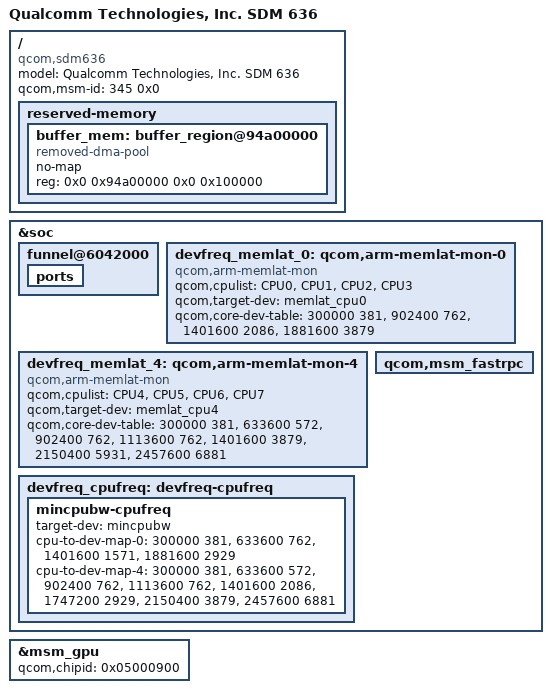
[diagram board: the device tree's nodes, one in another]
/* Copyright (c) 2017-2018, The Linux Foundation. All rights reserved.
 *
 * This program is free software; you can redistribute it and/or modify
 * it under the terms of the GNU General Public License version 2 and
 * only version 2 as published by the Free Software Foundation.
 *
 * This program is distributed in the hope that it will be useful,
 * but WITHOUT ANY WARRANTY; without even the implied warranty of
 * MERCHANTABILITY or FITNESS FOR A PARTICULAR PURPOSE.  See the
 * GNU General Public License for more details.
 */

#include "sdm660.dtsi"

/ {
	model = "Qualcomm Technologies, Inc. SDM 636";
	compatible = "qcom,sdm636";
	qcom,msm-id = <345 0x0>;

	reserved-memory {
		/delete-node/ cdsp_fw_region@94a00000;

		buffer_mem: buffer_region@94a00000 {
			compatible = "removed-dma-pool";
			no-map;
			reg = <0x0 0x94a00000 0x0 0x100000>;
		};
	};
};

&soc {
	/delete-node/ qcom,turing@1a300000;

	/delete-node/ qcom,msm-cdsp-loader;
	/delete-node/ cti@7068000;
	/delete-node/ turing_etm0;
	funnel@6042000 {
		ports {
			/delete-node/ port@4;
		};
	};

	devfreq_memlat_0: qcom,arm-memlat-mon-0 {
		compatible = "qcom,arm-memlat-mon";
		qcom,cpulist = <&CPU0 &CPU1 &CPU2 &CPU3>;
		qcom,target-dev = <&memlat_cpu0>;
		qcom,core-dev-table =
			< 300000 381 >,
			< 902400 762 >,
			< 1401600 2086 >,
			< 1881600 3879 >;
	};

	devfreq_memlat_4: qcom,arm-memlat-mon-4 {
		compatible = "qcom,arm-memlat-mon";
		qcom,cpulist = <&CPU4 &CPU5 &CPU6 &CPU7>;
		qcom,target-dev = <&memlat_cpu4>;
		qcom,core-dev-table =
			< 300000 381 >,
			< 633600 572 >,
			< 902400 762 >,
			< 1113600 762 >,
			< 1401600 3879 >,
			< 2150400 5931 >,
			< 2457600 6881 >;
	};

	devfreq_cpufreq: devfreq-cpufreq {
		mincpubw-cpufreq {
			target-dev = <&mincpubw>;
			cpu-to-dev-map-0 =
				< 300000 381 >,
				< 633600 762 >,
				< 1401600 1571 >,
				< 1881600 2929 >;
			cpu-to-dev-map-4 =
				< 300000 381 >,
				< 633600 572 >,
				< 902400 762 >,
				< 1113600 762 >,
				< 1401600 2086 >,
				< 1747200 2929 >,
				< 2150400 3879 >,
				< 2457600 6881 >;
		};
	};
};

&soc {
	/delete-node/ arm,smmu-turing_q6@5180000;
	qcom,msm_fastrpc {
		/delete-node/ qcom,msm_fastrpc_compute_cb5;
		/delete-node/ qcom,msm_fastrpc_compute_cb6;
		/delete-node/ qcom,msm_fastrpc_compute_cb7;
		/delete-node/ qcom,msm_fastrpc_compute_cb8;
		/delete-node/ qcom,msm_fastrpc_compute_cb9;
		/delete-node/ qcom,msm_fastrpc_compute_cb10;
		/delete-node/ qcom,msm_fastrpc_compute_cb11;
		/delete-node/ qcom,msm_fastrpc_compute_cb12;
		/delete-node/ qcom,msm_fastrpc_compute_cb13;
	};
};

/* GPU overrides */
&msm_gpu {
		/* Update GPU chip ID*/
		qcom,chipid = <0x05000900>;
};
